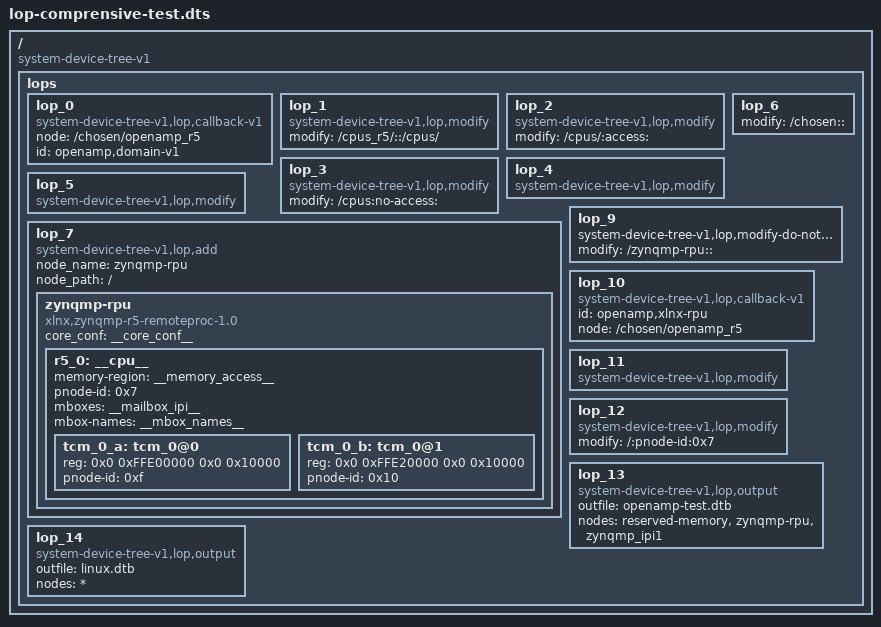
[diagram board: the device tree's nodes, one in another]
/dts-v1/;

/ {
        compatible = "system-device-tree-v1";
        lops {
                // compatible = "system-device-tree-v1,lop";
                lop_0 {
                        compatible = "system-device-tree-v1,lop,callback-v1";
                        node = "/chosen/openamp_r5";
                        id = "openamp,domain-v1";
                };
                lop_1 {
                        // node name modify
                        compatible = "system-device-tree-v1,lop,modify";
                        modify = "/cpus_r5/::/cpus/";
                };
                lop_2 {
                        compatible = "system-device-tree-v1,lop,modify";
                        // format is: "path":"property":"replacement"
                        //    - modify to "nothing", is a remove operation
                        //    - modify with no property is node operation (rename or remove)
                        modify = "/cpus/:access:";
                };
                lop_3 {
                        // modify to "nothing", is a remove operation
                        compatible = "system-device-tree-v1,lop,modify";
                        modify = "/cpus:no-access:";
                };
                lop_4 {
                        // node delete
                        compatible = "system-device-tree-v1,lop,modify";
                        // commented out. test purposes
                        // modify = "/amba/::";
                };
                lop_5 {
                        // node name modify
                        compatible = "system-device-tree-v1,lop,modify";
                        // commented out. test purposes
                        // modify = "/amba/::";
                };
                lop_6 {
                        // temp, temp, temp .. just testing if we can delete
                        // compatible = "system-device-tree-v1,lop,modify";
                        modify = "/chosen::";
                };
                lop_7 {
                        // node add
                        compatible = "system-device-tree-v1,lop,add";
                        node_name = "zynqmp-rpu";
                        node_path = "/";
                        zynqmp-rpu {
                            compatible = "xlnx,zynqmp-r5-remoteproc-1.0";
                            #address-cells = <2>;
                            #size-cells = <2>;
                            ranges;
                            core_conf = "__core_conf__";
                            r5_0: __cpu__ {
                                  // #address-cells = <2>;
                                  // #size-cells = <2>;
                                  // <0xF> indicates that it must be replaced
                                  #address-cells = <0xF>;
                                  #size-cells = <0xF>;
                                  ranges;
                                  // memory-region = <&rproc_0_reserved>, <&rproc_0_dma>;
                                  memory-region = <&__memory_access__>;
                                  pnode-id = <0x7>;
                                  // mboxes = <&ipi_mailbox_rpu0 0>, <&ipi_mailbox_rpu0 1>;
                                  mboxes = <&__mailbox_ipi__>;
                                  // mbox-names = "tx", "rx";
                                  mbox-names = "__mbox_names__";
                                  tcm_0_a: tcm_0@0 {
                                           reg = <0x0 0xFFE00000 0x0 0x10000>;
                                           pnode-id = <0xf>;
                                  };
                                  tcm_0_b: tcm_0@1 {
                                         reg = <0x0 0xFFE20000 0x0 0x10000>;
                                         pnode-id = <0x10>;
                                  };
                            };
                        };
                  };
                  lop_9 {
                          // temp temp temp, can we modify a recently added node ??
                          compatible = "system-device-tree-v1,lop,modify-do-not-use";
                          modify = "/zynqmp-rpu::";
                  };
                  lop_10 {
                          // optionally execute a routine in a loaded module. If the routine
                          // isn't found, this is NOT a failure. Since we don't want to tightly
                          // couple these transforms and loaded modules
                          compatible = "system-device-tree-v1,lop,callback-v1";
                          // TODO: put a node compatible string here
                          // module = "openamp,xlnx-rpu";
                          id = "openamp,xlnx-rpu";
                          node = "/chosen/openamp_r5";
                          // callback = "xlnx_openamp_rpu";
                  };
                  lop_11 {
                        // property value modify
                        compatible = "system-device-tree-v1,lop,modify";
                        // disabled for now: will be put in a test transforms .dts file
                        // modify = "/:model:this is a test";
                 };
                 lop_12 {
                        // test: property add
                        // example: add a special ID into various nodes
                        compatible = "system-device-tree-v1,lop,modify";
                        // disabled for now: will be put in a test transforms .dts file
                        modify = "/:pnode-id:0x7";
                 };
                 lop_13 {
                        compatible = "system-device-tree-v1,lop,output";
                        outfile = "openamp-test.dtb";
                        nodes = "reserved-memory", "zynqmp-rpu", "zynqmp_ipi1";
                 };
                 lop_14 {
                        compatible = "system-device-tree-v1,lop,output";
                        outfile = "linux.dtb";
                        nodes = "*";
                 };
        };
};
